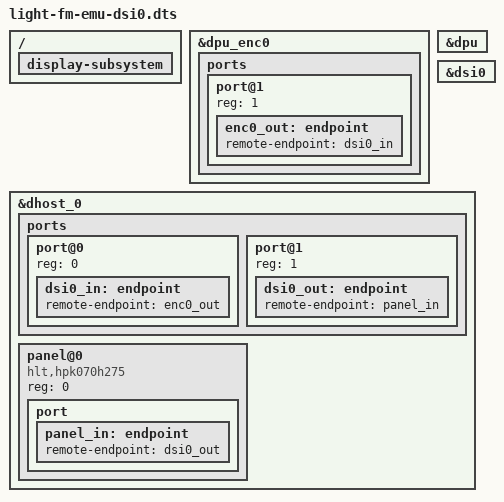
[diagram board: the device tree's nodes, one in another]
#include "light-fm-emu.dts"

/ {
	display-subsystem {
		status = "okay";
	};
};

&dpu_enc0 {
	status = "okay";

	ports {
		/* output */
		port@1 {
			reg = <1>;

			enc0_out: endpoint {
				remote-endpoint = <&dsi0_in>;
			};
		};
	};
};

&dpu {
        status = "okay";
};

&dsi0 {
        status = "okay";
};

&dhost_0 {
	ports {
		#address-cells = <1>;
		#size-cells = <0>;

		port@0 {
			reg = <0>;

			dsi0_in: endpoint {
				remote-endpoint = <&enc0_out>;
			};
		};

		port@1 {
			reg = <1>;

			dsi0_out: endpoint {
				remote-endpoint = <&panel_in>;
			};
		};
	};

	panel@0 {
		compatible = "hlt,hpk070h275";
		reg = <0>;

		port {
			panel_in: endpoint {
				remote-endpoint = <&dsi0_out>;
			};
		};
	};
};
